# platform_designer_hps_system_hps_0_hps register map
Vendor: default_vendor.com; File version: 0.0
Registers are 32-bit, read-write, reset 0x0 unless marked. A register's access mark holds for its fields unless they carry their own. Offsets are from the block's base; [hi:lo] are bit positions.

## fpgamgrregs — Registers in the FPGA Manager module accessible via its APB slave
Base 0xFF706000
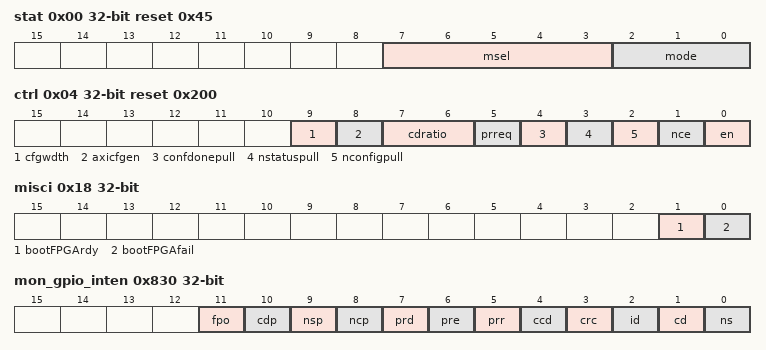
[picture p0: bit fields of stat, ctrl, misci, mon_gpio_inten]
0x00 stat reset 0x45 — Provides status fields for software for the FPGA Manager. The Mode field tells software what configuration phase the FPGA currently is in. For regular configuration through the PINs or through the HPS, these states map directly to customer configuration documentation. For Configuration Via PCI Express (CVP), the IOCSR configuration is done through the PINS or through HPS. Then the complete configuration is done through the PCI Express Bus. When CVP is being done, InitPhase indicates only IOCSR configuration has completed. CVP_CONF_DONE is available in the CB Monitor for observation by software. The MSEL field provides a read only register for software to read the MSEL value driven from the external pins.
  [7:3] msel ro — This read-only field allows software to observe the MSEL inputs from the device pins. The MSEL pins define the FPGA configuration mode.
    0=PP16_FAST_NOAES_NODC; 1=PP16_FAST_AES_NODC; 2=PP16_FAST_AESOPT_DC; 4=PP16_SLOW_NOAES_NODC; 5=PP16_SLOW_AES_NODC; 6=PP16_SLOW_AESOPT_DC; 8=PP32_FAST_NOAES_NODC; 9=PP32_FAST_AES_NODC; 10=PP32_FAST_AESOPT_DC; 12=PP32_SLOW_NOAES_NODC; 13=PP32_SLOW_AES_NODC; 14=PP32_SLOW_AESOPT_DC
  [2:0] mode — Reports FPGA state
    0=FPGAOff; 1=ResetPhase; 2=CfgPhase; 3=InitPhase; 4=UserMode; 5=Unknown
0x04 ctrl reset 0x200 — Allows HPS to control FPGA configuration. The NCONFIGPULL, NSTATUSPULL, and CONFDONEPULL fields drive signals to the FPGA Control Block that are logically ORed into their respective pins. These signals are always driven independent of the value of EN. The polarity of the NCONFIGPULL, NSTATUSPULL, and CONFDONEPULL fields is inverted relative to their associated pins. The MSEL (external pins), CDRATIO and CFGWDTH signals determine the mode of operation for Normal Configuration. For Partial Reconfiguration, CDRATIO is used to set the appropriate clock to data ratio, and CFGWDTH should always be set to 16-bit Passive Parallel. AXICFGEN is used to enable transfer of configuration data by enabling or disabling DCLK during data transfers.
  [9] cfgwdth — This field determines the Configuration Passive Parallel data bus width when HPS configures the FPGA. Only 32-bit Passive Parallel or 16-bit Passive Parallel are supported. When HPS does Normal Configuration, configuration should use 32-bit Passive Parallel Mode. The external pins MSEL must be set appropriately for the configuration selected. For Partial Reconfiguration, 16-bit Passive Parallel must be used.
    0=PPx16; 1=PPx32
  [8] axicfgen — There are strict SW initialization steps for configuration, partial configuration and error cases. When SW is sending configuration files, this bit must be set before the file is transferred on the AXI bus. This bit enables the DCLK during the AXI configuration data transfers. Note, the AXI and configuration datapaths remain active irregardless of the state of this bit. Simply, if the AXI slave is enabled, the DCLK to the CB will be active. If disabled, the DCLK to the CB will not be active. So AXI transfers destined to the FPGA Manager when AXIEN is 0, will complete normally from the HPS perspective. This field only affects the FPGA if CTRL.EN is 1.
    0=disabled; 1=enabled
  [7:6] cdratio — This field controls the Clock to Data Ratio (CDRATIO) for Normal Configuration and Partial Reconfiguration data transfer from the AXI Slave to the FPGA. For Normal Configuration, the value in this field must be set to be consistent to the implied CD ratio of the MSEL setting. For Partial Reconfiguration, the value in this field must be set to the same clock to data ratio in the options bits in the Normal Configuration file.
    0=x1; 1=x2; 2=x4; 3=x8
  [5] prreq — This field is used to assert PR_REQUEST to request partial reconfiguration while the FPGA is in User Mode. This field only affects the FPGA if CTRL.EN is 1.
    0=deassert; 1=assert
  [4] confdonepull — Pulls down CONF_DONE input to the CB
    0=dont_pulldown; 1=pulldown
  [3] nstatuspull — Pulls down nSTATUS input to the CB
    0=dont_pulldown; 1=pulldown
  [2] nconfigpull — The nCONFIG input is used to put the FPGA into its reset phase. If the FPGA was configured, its operation stops and it will have to be configured again to start operation.
    0=dont_pulldown; 1=pulldown
  [1] nce — This field drives the active-low Chip Enable (nCE) signal to the CB. It should be set to 0 (configuration enabled) before CTRL.EN is set. This field only effects the FPGA if CTRL.EN is 1.
    0=Cfg_Enabled; 1=Cfg_Disabled
  [0] en — Controls whether the FPGA configuration pins or HPS FPGA Manager drive configuration inputs to the CB.
    0=FPGA_Pins_Control_Cfg; 1=FPGAMGR_Controls_Cfg
0x08 dclkcnt — Used to give software control in enabling DCLK at any time. SW will need control of the DCLK in specific configuration and partial reconfiguration initialization steps to send spurious DCLKs required by the CB. SW takes ownership for DCLK during normal configuration, partial reconfiguration, error scenerio handshakes including SEU CRC error during partial reconfiguration, SW early abort of partial reconfiguration, and initializatin phase DCLK driving. During initialization phase, a configuration image loaded into the FPGA can request that DCLK be used as the initialization phase clock instead of the default internal oscillator or optionally the CLKUSR pin. In the case that DCLK is requested, the DCLKCNT register is used by software to control DCLK during the initialization phase. Software should poll the DCLKSTAT.DCNTDONE write one to clear register to be set when the correct number of DCLKs have completed. Software should clear DCLKSTAT.DCNTDONE before writing to the DCLKCNT register again. This field only affects the FPGA if CTRL.EN is 1.
  [31:0] cnt — Controls DCLK counter. Software writes a non-zero value into CNT and the FPGA Manager generates the specified number of DCLK pulses and decrements COUNT. This register will read back the original value written by software. Software can write CNT at any time.
0x0C dclkstat — This write one to clear register indicates that the DCLKCNT has counted down to zero. The DCLKCNT is used by software to drive spurious DCLKs to the FPGA. Software will poll this bit after writing DCLKCNT to know when all of the DCLKs have been sent.
  [0] dcntdone write-1-clears — This bit is write one to clear. This bit gets set after the DCLKCNT has counted down to zero (transition from 1 to 0).
    0=notdone; 1=done
0x10 gpo — Provides a low-latency, low-performance, and simple way to drive general-purpose signals to the FPGA fabric.
  [31:0] value — Drives h2f_gp[31:0] with specified value. When read, returns the current value being driven to the FPGA fabric.
0x14 gpi ro reset not defined — Provides a low-latency, low-performance, and simple way to read general-purpose signals driven from the FPGA fabric.
  [31:0] value — The value being driven from the FPGA fabric on f2h_gp[31:0]. If the FPGA is not in User Mode, the value of this field is undefined.
0x18 misci ro (reset mask 0xFFFFFFFC) — Provides a low-latency, low-performance, and simple way to read specific handshaking signals driven from the FPGA fabric.
  [1] bootFPGArdy — The value of the f2h_boot_from_fpga_ready signal from the FPGA fabric. If the FPGA is not in User Mode, the value of this field is undefined. 1 = FPGA fabric is ready to accept AXI master requests from the HPS2FPGA bridge. 0 = FPGA fabric is not ready (probably still processing a reset).
  [0] bootFPGAfail — The value of the f2h_boot_from_fpga_on_failure signal from the FPGA fabric. If the FPGA is not in User Mode, the value of this field is undefined. 1 = Boot ROM will boot from FPGA if boot from normal boot device fails. 0 = Boot ROM will not boot from FPGA if boot from normal boot device fails.
0x830 mon_gpio_inten — Allows each bit of Port A to be configured to generate an interrupt or not.
  [all] fields
    0=disable; 1=enable
  [11] fpo — Enables interrupt generation for FPGA_POWER_ON
  [10] cdp — Enables interrupt generation for CONF_DONE Pin
  [9] nsp — Enables interrupt generation for nSTATUS Pin
  [8] ncp — Enables interrupt generation for nCONFIG Pin
  [7] prd — Enables interrupt generation for PR_DONE
  [6] pre — Enables interrupt generation for PR_ERROR
  [5] prr — Enables interrupt generation for PR_READY
  [4] ccd — Enables interrupt generation for CVP_CONF_DONE
  [3] crc — Enables interrupt generation for CRC_ERROR
  [2] id — Enables interrupt generation for INIT_DONE
  [1] cd — Enables interrupt generation for CONF_DONE
  [0] ns — Enables interrupt generation for nSTATUS
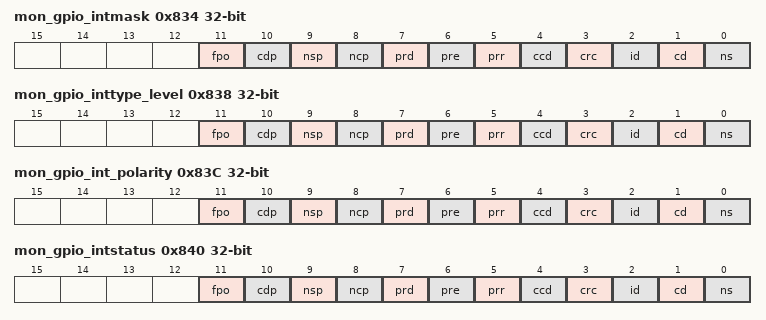
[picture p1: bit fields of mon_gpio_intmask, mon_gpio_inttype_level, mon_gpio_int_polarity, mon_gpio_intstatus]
0x834 mon_gpio_intmask — This register has 12 individual interrupt masks for the MON. Controls whether an interrupt on Port A can create an interrupt for the interrupt controller by not masking it. By default, all interrupts bits are unmasked. Whenever a 1 is written to a bit in this register, it masks the interrupt generation capability for this signal; otherwise interrupts are allowed through. The unmasked status can be read as well as the resultant status after masking.
  [all] fields
    0=disable; 1=enable
  [11] fpo — Controls whether an interrupt for FPGA_POWER_ON can generate an interrupt to the interrupt controller by not masking it. The unmasked status can be read as well as the resultant status after masking.
  [10] cdp — Controls whether an interrupt for CONF_DONE Pin can generate an interrupt to the interrupt controller by not masking it. The unmasked status can be read as well as the resultant status after masking.
  [9] nsp — Controls whether an interrupt for nSTATUS Pin can generate an interrupt to the interrupt controller by not masking it. The unmasked status can be read as well as the resultant status after masking.
  [8] ncp — Controls whether an interrupt for nCONFIG Pin can generate an interrupt to the interrupt controller by not masking it. The unmasked status can be read as well as the resultant status after masking.
  [7] prd — Controls whether an interrupt for PR_DONE can generate an interrupt to the interrupt controller by not masking it. The unmasked status can be read as well as the resultant status after masking.
  [6] pre — Controls whether an interrupt for PR_ERROR can generate an interrupt to the interrupt controller by not masking it. The unmasked status can be read as well as the resultant status after masking.
  [5] prr — Controls whether an interrupt for PR_READY can generate an interrupt to the interrupt controller by not masking it. The unmasked status can be read as well as the resultant status after masking.
  [4] ccd — Controls whether an interrupt for CVP_CONF_DONE can generate an interrupt to the interrupt controller by not masking it. The unmasked status can be read as well as the resultant status after masking.
  [3] crc — Controls whether an interrupt for CRC_ERROR can generate an interrupt to the interrupt controller by not masking it. The unmasked status can be read as well as the resultant status after masking.
  [2] id — Controls whether an interrupt for INIT_DONE can generate an interrupt to the interrupt controller by not masking it. The unmasked status can be read as well as the resultant status after masking.
  [1] cd — Controls whether an interrupt for CONF_DONE can generate an interrupt to the interrupt controller by not masking it. The unmasked status can be read as well as the resultant status after masking.
  [0] ns — Controls whether an interrupt for nSTATUS can generate an interrupt to the interrupt controller by not masking it. The unmasked status can be read as well as the resultant status after masking.
0x838 mon_gpio_inttype_level — The interrupt level register defines the type of interrupt (edge or level) for each GPIO input.
  [all] fields
    0=level; 1=edge
  [11] fpo — Controls whether the level of FPGA_POWER_ON or an edge on FPGA_POWER_ON generates an interrupt.
  [10] cdp — Controls whether the level of CONF_DONE Pin or an edge on CONF_DONE Pin generates an interrupt.
  [9] nsp — Controls whether the level of nSTATUS Pin or an edge on nSTATUS Pin generates an interrupt.
  [8] ncp — Controls whether the level of nCONFIG Pin or an edge on nCONFIG Pin generates an interrupt.
  [7] prd — Controls whether the level of PR_DONE or an edge on PR_DONE generates an interrupt.
  [6] pre — Controls whether the level of PR_ERROR or an edge on PR_ERROR generates an interrupt.
  [5] prr — Controls whether the level of PR_READY or an edge on PR_READY generates an interrupt.
  [4] ccd — Controls whether the level of CVP_CONF_DONE or an edge on CVP_CONF_DONE generates an interrupt.
  [3] crc — Controls whether the level of CRC_ERROR or an edge on CRC_ERROR generates an interrupt.
  [2] id — Controls whether the level of INIT_DONE or an edge on INIT_DONE generates an interrupt.
  [1] cd — Controls whether the level of CONF_DONE or an edge on CONF_DONE generates an interrupt.
  [0] ns — Controls whether the level of nSTATUS or an edge on nSTATUS generates an interrupt.
0x83C mon_gpio_int_polarity — Controls the polarity of interrupts that can occur on each GPIO input.
  [all] fields
    0=actlow; 1=acthigh
  [11] fpo — Controls the polarity of edge or level sensitivity for FPGA_POWER_ON
  [10] cdp — Controls the polarity of edge or level sensitivity for CONF_DONE Pin
  [9] nsp — Controls the polarity of edge or level sensitivity for nSTATUS Pin
  [8] ncp — Controls the polarity of edge or level sensitivity for nCONFIG Pin
  [7] prd — Controls the polarity of edge or level sensitivity for PR_DONE
  [6] pre — Controls the polarity of edge or level sensitivity for PR_ERROR
  [5] prr — Controls the polarity of edge or level sensitivity for PR_READY
  [4] ccd — Controls the polarity of edge or level sensitivity for CVP_CONF_DONE
  [3] crc — Controls the polarity of edge or level sensitivity for CRC_ERROR
  [2] id — Controls the polarity of edge or level sensitivity for INIT_DONE
  [1] cd — Controls the polarity of edge or level sensitivity for CONF_DONE
  [0] ns — Controls the polarity of edge or level sensitivity for nSTATUS
0x840 mon_gpio_intstatus ro — Reports on interrupt status for each GPIO input. The interrupt status includes the effects of masking.
  [all] fields
    0=inactive; 1=active
  [11] fpo — Indicates whether FPGA_POWER_ON has an active interrupt or not (after masking).
  [10] cdp — Indicates whether CONF_DONE Pin has an active interrupt or not (after masking).
  [9] nsp — Indicates whether nSTATUS Pin has an active interrupt or not (after masking).
  [8] ncp — Indicates whether nCONFIG Pin has an active interrupt or not (after masking).
  [7] prd — Indicates whether PR_DONE has an active interrupt or not (after masking).
  [6] pre — Indicates whether PR_ERROR has an active interrupt or not (after masking).
  [5] prr — Indicates whether PR_READY has an active interrupt or not (after masking).
  [4] ccd — Indicates whether CVP_CONF_DONE has an active interrupt or not (after masking).
  [3] crc — Indicates whether CRC_ERROR has an active interrupt or not (after masking).
  [2] id — Indicates whether INIT_DONE has an active interrupt or not (after masking).
  [1] cd — Indicates whether CONF_DONE has an active interrupt or not (after masking).
  [0] ns — Indicates whether nSTATUS has an active interrupt or not (after masking).
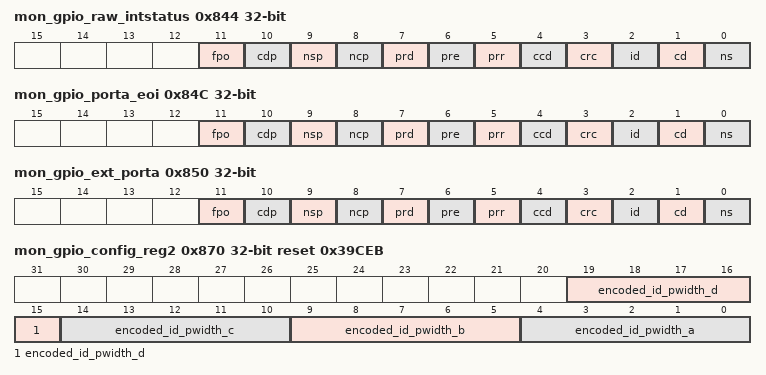
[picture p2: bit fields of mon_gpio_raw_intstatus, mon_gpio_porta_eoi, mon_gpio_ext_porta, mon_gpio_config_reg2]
0x844 mon_gpio_raw_intstatus ro — Reports on raw interrupt status for each GPIO input. The raw interrupt status excludes the effects of masking.
  [all] fields
    0=inactive; 1=active
  [11] fpo — Indicates whether FPGA_POWER_ON has an active interrupt or not (before masking).
  [10] cdp — Indicates whether CONF_DONE Pin has an active interrupt or not (before masking).
  [9] nsp — Indicates whether nSTATUS Pin has an active interrupt or not (before masking).
  [8] ncp — Indicates whether nCONFIG Pin has an active interrupt or not (before masking).
  [7] prd — Indicates whether PR_DONE has an active interrupt or not (before masking).
  [6] pre — Indicates whether PR_ERROR has an active interrupt or not (before masking).
  [5] prr — Indicates whether PR_READY has an active interrupt or not (before masking).
  [4] ccd — Indicates whether CVP_CONF_DONE has an active interrupt or not (before masking).
  [3] crc — Indicates whether CRC_ERROR has an active interrupt or not (before masking).
  [2] id — Indicates whether INIT_DONE has an active interrupt or not (before masking).
  [1] cd — Indicates whether CONF_DONE has an active interrupt or not (before masking).
  [0] ns — Indicates whether nSTATUS has an active interrupt or not (before masking).
0x84C mon_gpio_porta_eoi wo — This register is written by software to clear edge interrupts generated by each individual GPIO input. This register always reads back as zero.
  [all] fields
    0=noclr; 1=clr
  [11] fpo — Used by software to clear an FPGA_POWER_ON edge interrupt.
  [10] cdp — Used by software to clear an CONF_DONE Pin edge interrupt.
  [9] nsp — Used by software to clear an nSTATUS Pin edge interrupt.
  [8] ncp — Used by software to clear an nCONFIG Pin edge interrupt.
  [7] prd — Used by software to clear an PR_DONE edge interrupt.
  [6] pre — Used by software to clear an PR_ERROR edge interrupt.
  [5] prr — Used by software to clear an PR_READY edge interrupt.
  [4] ccd — Used by software to clear an CVP_CONF_DONE edge interrupt.
  [3] crc — Used by software to clear an CRC_ERROR edge interrupt.
  [2] id — Used by software to clear an INIT_DONE edge interrupt.
  [1] cd — Used by software to clear an CONF_DONE edge interrupt.
  [0] ns — Used by software to clear an nSTATUS edge interrupt.
0x850 mon_gpio_ext_porta ro — Reading this register reads the values of the GPIO inputs.
  [11] fpo — Reading this provides the value of FPGA_POWER_ON
  [10] cdp — Reading this provides the value of CONF_DONE Pin
  [9] nsp — Reading this provides the value of nSTATUS Pin
  [8] ncp — Reading this provides the value of nCONFIG Pin
  [7] prd — Reading this provides the value of PR_DONE
  [6] pre — Reading this provides the value of PR_ERROR
  [5] prr — Reading this provides the value of PR_READY
  [4] ccd — Reading this provides the value of CVP_CONF_DONE
  [3] crc — Reading this provides the value of CRC_ERROR
  [2] id — Reading this provides the value of INIT_DONE
  [1] cd — Reading this provides the value of CONF_DONE
  [0] ns — Reading this provides the value of nSTATUS
0x860 mon_gpio_ls_sync — The Synchronization level register is used to synchronize inputs to the l4_mp_clk. All MON interrupts are already synchronized before the GPIO instance so it is not necessary to setup this register to enable synchronization.
  [0] gpio_ls_sync — The level-sensitive interrupts is synchronized to l4_mp_clk.
    0=nosync; 1=sync
0x86C mon_gpio_ver_id_code ro reset 0x3230382A — GPIO Component Version
  [31:0] gpio_ver_id_code — ASCII value for each number in the version, followed by *. For example. 32_30_31_2A represents the version 2.01
0x870 mon_gpio_config_reg2 ro reset 0x39CEB — Specifies the bit width of port A.
  [all] fields
    7=widthlessone8bits; 11=widthlessone12bits
  [19:15] encoded_id_pwidth_d — Specifies the width of GPIO Port D. Ignored because there is no Port D in the GPIO.
  [14:10] encoded_id_pwidth_c — Specifies the width of GPIO Port C. Ignored because there is no Port C in the GPIO.
  [9:5] encoded_id_pwidth_b — Specifies the width of GPIO Port B. Ignored because there is no Port B in the GPIO.
  [4:0] encoded_id_pwidth_a — Specifies the width of GPIO Port A. The value 11 represents the 12-bit width less one.
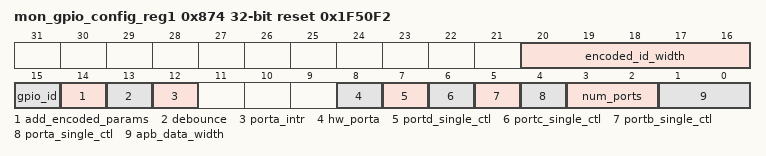
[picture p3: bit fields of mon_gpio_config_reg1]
0x874 mon_gpio_config_reg1 ro reset 0x1F50F2 — Reports settings of various GPIO configuration parameters
  [20:16] encoded_id_width — This value is fixed at 32 bits.
    31=encidwidth
  [15] gpio_id — Provides an ID code value
    0=idcode_excluded
  [14] add_encoded_params — Fixed to allow the indentification of the Designware IP component.
    1=addencparams
  [13] debounce — The value of this field is fixed to not allow debouncing of the Port A signals.
    0=debouncea_disabled
  [12] porta_intr — The value of this field is fixed to allow interrupts on Port A.
    1=portainterr
  [8] hw_porta — The value is fixed to enable Port A configuration to be controlled by software only.
    0=portanohard
  [7] portd_single_ctl — Indicates the mode of operation of Port D to be software controlled only. Ignored because there is no Port D in the GPIO.
    1=softctlonly
  [6] portc_single_ctl — Indicates the mode of operation of Port C to be software controlled only. Ignored because there is no Port C in the GPIO.
    1=softctlonly
  [5] portb_single_ctl — Indicates the mode of operation of Port B to be software controlled only. Ignored because there is no Port B in the GPIO.
    1=softctlonly
  [4] porta_single_ctl — Indicates the mode of operation of Port A to be software controlled only.
    1=softctlonly
  [3:2] num_ports — The value of this register is fixed at one port (Port A).
    0=oneporta
  [1:0] apb_data_width — Fixed to support an APB data bus width of 32-bits.
    2=width32bits
